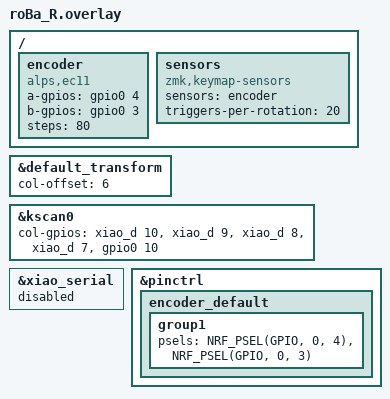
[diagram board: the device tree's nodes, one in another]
#include "roBa.dtsi"

&default_transform {
    col-offset = <6>;
};

&kscan0 {
    col-gpios
        = <&xiao_d 10 GPIO_ACTIVE_HIGH>
        , <&xiao_d 9 GPIO_ACTIVE_HIGH> 
        , <&xiao_d 8 GPIO_ACTIVE_HIGH> 
        , <&xiao_d 7 GPIO_ACTIVE_HIGH> 
        , <&gpio0 10 GPIO_ACTIVE_HIGH>
        ;
};

&xiao_serial { status = "disabled"; };

// ロータリーエンコーダー設定
&pinctrl {
    encoder_default: encoder_default {
        group1 {
            psels = <NRF_PSEL(GPIO, 0, 4)>,
                <NRF_PSEL(GPIO, 0, 3)>;
        };
    };
};

/ {
    encoder: encoder {
        compatible = "alps,ec11";
        a-gpios = <&gpio0 4 (GPIO_ACTIVE_HIGH | GPIO_PULL_UP)>;
        b-gpios = <&gpio0 3 (GPIO_ACTIVE_HIGH | GPIO_PULL_UP)>;
        steps = <80>;
        status = "okay";
    };

    sensors: sensors {
        compatible = "zmk,keymap-sensors";
        sensors = <&encoder>;
        triggers-per-rotation = <20>;
    };
};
